AUTOSAR XML (schema 00048)
package /ComponentTypes
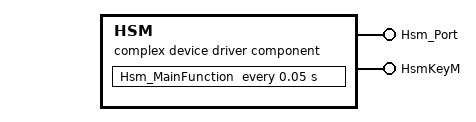
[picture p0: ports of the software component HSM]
  complex device driver sw component type HSM
    provide port Hsm_Port: server-com-spec{operation=TrngGenerate, queue-length=1}, provided-interface=Hsm_Port
    provide port HsmKeyM: provided-interface=HsmKeyM
      provided-com-specs:
        operation=GetAes128Key, queue-length=1
        operation=GetCmacKey, queue-length=1
        operation=GetCmacKeyState, queue-length=1
        operation=SetAes128Key, queue-length=1
        operation=SetCmacKey, queue-length=1
    behavior HSM_InternalBehavior
      timing event TMT_Hsm_MainFunction: start-on-event=Hsm_MainFunction, period=0.05
      6 x operation invoked event:
        OIT_HsmGetCmacKey_HsmKeyM_GetCmacKey: start-on-event=HsmGetCmacKey, operation=HsmKeyM.GetCmacKey
        OIT_Runnable_HsmKeyM_GetCmacKeyState: start-on-event=HsmGetCmacKeyState, operation=HsmKeyM.GetCmacKeyState
        OIT_HsmSetCmacKey_HsmKeyM_SetCmacKey: start-on-event=HsmSetCmacKey, operation=HsmKeyM.SetCmacKey
        OIT_HsmTrngGenerate_Hsm_Port_TrngGenerate: start-on-event=HsmTrngGenerate, operation=Hsm_Port.TrngGenerate
        OIT_Runnable_HsmKeyM_SetAes128Key: start-on-event=HsmSetAes128Key, operation=HsmKeyM.SetAes128Key
        OIT_Runnable_1_HsmKeyM_GetAes128Key: start-on-event=HsmGetAes128Key, operation=HsmKeyM.GetAes128Key
      7 x runnable:
        Hsm_MainFunction
        HsmGetCmacKey: can-be-invoked-concurrently=true
        HsmGetCmacKeyState: can-be-invoked-concurrently=true
        HsmSetCmacKey: can-be-invoked-concurrently=true
        HsmTrngGenerate: can-be-invoked-concurrently=true
        HsmSetAes128Key
        HsmGetAes128Key
  swc implementation HSM_Implementation: behavior=HSM_InternalBehavior
    code-descriptors:
      code Default: artifact-descriptors=autosar-engineering-object=category=SWSRC
